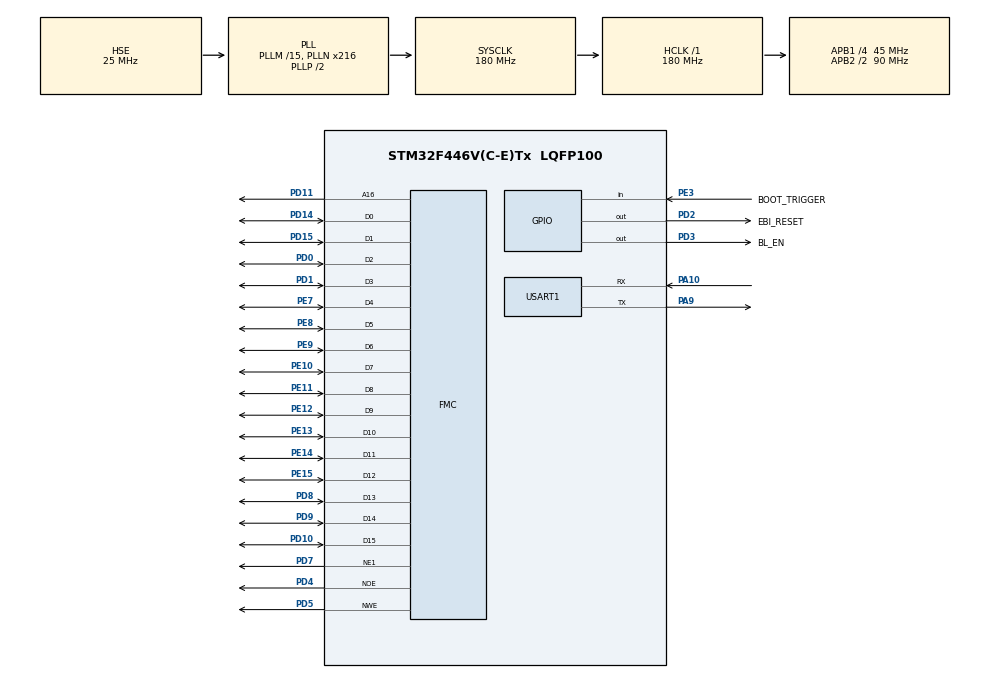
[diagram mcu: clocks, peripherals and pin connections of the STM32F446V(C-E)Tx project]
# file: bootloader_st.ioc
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Mcu.Family=STM32F4
Mcu.Name=STM32F446V(C-E)Tx
Mcu.Package=LQFP100
NVIC.PriorityGroup=NVIC_PRIORITYGROUP_4
NVIC.USART1_IRQn=true\:0\:0\:false\:false\:true
PA10.Mode=Asynchronous
PA10.Signal=USART1_RX
PA9.Mode=Asynchronous
PA9.Signal=USART1_TX
PD0.Mode=16b-d1
PD0.Signal=FMC_D2
PD1.Mode=16b-d1
PD1.Signal=FMC_D3
PD10.Mode=16b-d1
PD10.Signal=FMC_D15
PD11.Mode=A16_1
PD11.Signal=FMC_A16
PD14.Mode=16b-d1
PD14.Signal=FMC_D0
PD15.Mode=16b-d1
PD15.Signal=FMC_D1
PD2.GPIO_Label=EBI_RESET
PD2.Signal=GPIO_Output
PD3.GPIO_Label=BL_EN
PD3.Signal=GPIO_Output
PD4.Mode=Lcd1
PD4.Signal=FMC_NOE
PD5.Mode=Lcd1
PD5.Signal=FMC_NWE
PD7.Mode=NorPsramChipSelect1_1
PD7.Signal=FMC_NE1
PD8.Mode=16b-d1
PD8.Signal=FMC_D13
PD9.Mode=16b-d1
PD9.Signal=FMC_D14
PE10.Mode=16b-d1
PE10.Signal=FMC_D7
PE11.Mode=16b-d1
PE11.Signal=FMC_D8
PE12.Mode=16b-d1
PE12.Signal=FMC_D9
PE13.Mode=16b-d1
PE13.Signal=FMC_D10
PE14.Mode=16b-d1
PE14.Signal=FMC_D11
PE15.Mode=16b-d1
PE15.Signal=FMC_D12
PE3.GPIO_Label=BOOT_TRIGGER
PE3.Signal=GPIO_Input
PE7.Mode=16b-d1
PE7.Signal=FMC_D4
PE8.Mode=16b-d1
PE8.Signal=FMC_D5
PE9.Mode=16b-d1
PE9.Signal=FMC_D6
PH0-OSC_IN.Mode=HSE-External-Oscillator
PH0-OSC_IN.Signal=RCC_OSC_IN
PH1-OSC_OUT.Mode=HSE-External-Oscillator
PH1-OSC_OUT.Signal=RCC_OSC_OUT
ProjectManager.HeapSize=0x200
ProjectManager.StackSize=0x400
ProjectManager.TargetToolchain=EWARM
RCC.AHBFreq_Value=180000000
RCC.APB1CLKDivider=RCC_HCLK_DIV4
RCC.APB1Freq_Value=45000000
RCC.APB1TimFreq_Value=90000000
RCC.APB2CLKDivider=RCC_HCLK_DIV2
RCC.APB2Freq_Value=90000000
RCC.APB2TimFreq_Value=180000000
RCC.CortexFreq_Value=180000000
RCC.HCLKFreq_Value=180000000
RCC.PLLM=15
RCC.PLLN=216
RCC.PLLSourceVirtual=RCC_PLLSOURCE_HSE
RCC.SYSCLKFreq_VALUE=180000000
RCC.SYSCLKSource=RCC_SYSCLKSOURCE_PLLCLK
RCC.USBFreq_Value=180000000
RCC.VCOOutputFreq_Value=360000000
USART1.VirtualMode=VM_ASYNC
board=bootloader_st

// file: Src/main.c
/**
  ******************************************************************************
  * File Name          : main.c
  * Description        : Main program body
  ******************************************************************************
  ** This notice applies to any and all portions of this file
  * that are not between comment pairs USER CODE BEGIN and
  * USER CODE END. Other portions of this file, whether
  * inserted by the user or by software development tools
  * are owned by their respective copyright owners.
  *
  * COPYRIGHT(c) 2017 STMicroelectronics
  *
  * Redistribution and use in source and binary forms, with or without modification,
  * are permitted provided that the following conditions are met:
  *   1. Redistributions of source code must retain the above copyright notice,
  *      this list of conditions and the following disclaimer.
  *   2. Redistributions in binary form must reproduce the above copyright notice,
  *      this list of conditions and the following disclaimer in the documentation
  *      and/or other materials provided with the distribution.
  *   3. Neither the name of STMicroelectronics nor the names of its contributors
  *      may be used to endorse or promote products derived from this software
  *      without specific prior written permission.
  *
  * THIS SOFTWARE IS PROVIDED BY THE COPYRIGHT HOLDERS AND CONTRIBUTORS "AS IS"
  * AND ANY EXPRESS OR IMPLIED WARRANTIES, INCLUDING, BUT NOT LIMITED TO, THE
  * IMPLIED WARRANTIES OF MERCHANTABILITY AND FITNESS FOR A PARTICULAR PURPOSE ARE
  * DISCLAIMED. IN NO EVENT SHALL THE COPYRIGHT HOLDER OR CONTRIBUTORS BE LIABLE
  * FOR ANY DIRECT, INDIRECT, INCIDENTAL, SPECIAL, EXEMPLARY, OR CONSEQUENTIAL
  * DAMAGES (INCLUDING, BUT NOT LIMITED TO, PROCUREMENT OF SUBSTITUTE GOODS OR
  * SERVICES; LOSS OF USE, DATA, OR PROFITS; OR BUSINESS INTERRUPTION) HOWEVER
  * CAUSED AND ON ANY THEORY OF LIABILITY, WHETHER IN CONTRACT, STRICT LIABILITY,
  * OR TORT (INCLUDING NEGLIGENCE OR OTHERWISE) ARISING IN ANY WAY OUT OF THE USE
  * OF THIS SOFTWARE, EVEN IF ADVISED OF THE POSSIBILITY OF SUCH DAMAGE.
  *
  ******************************************************************************
  */
#include "main.h"
#include "stm32f4xx_hal.h"

/* USER CODE BEGIN Includes */
#include "bootloader.h"
/* USER CODE END Includes */

UART_HandleTypeDef huart1;

SRAM_HandleTypeDef hsram1;

/* USER CODE BEGIN PV */
/* Private variables ---------------------------------------------------------*/

/* USER CODE END PV */

void SystemClock_Config(void);
static void MX_GPIO_Init(void);
static void MX_FMC_Init(void);
static void MX_USART1_UART_Init(void);

/* USER CODE BEGIN PFP */
/* Private function prototypes -----------------------------------------------*/
#ifdef __GNUC__
/* With GCC, small printf (option LD Linker->Libraries->Small printf
   set to 'Yes') calls __io_putchar() */
#define PUTCHAR_PROTOTYPE int __io_putchar(int ch)
#else
#define PUTCHAR_PROTOTYPE int fputc(int ch, FILE *f)
#endif /* __GNUC__ */

/* USER CODE END PFP */

int main(void)
{

  /* MCU Configuration----------------------------------------------------------*/

  /* Reset of all peripherals, Initializes the Flash interface and the Systick. */
  HAL_Init();

  /* Configure the system clock */
  SystemClock_Config();

  /* Initialize all configured peripherals */
  MX_GPIO_Init();
  MX_FMC_Init();
  MX_USART1_UART_Init();

  /* USER CODE BEGIN 2 */
  Bootloader_Initialize();

  /* USER CODE END 2 */

  /* Infinite loop */
  /* USER CODE BEGIN WHILE */
  while (1)
  {
        Bootloader_Tasks();

  /* USER CODE END WHILE */

  }

}

/** System Clock Configuration
*/
void SystemClock_Config(void)
{

  RCC_OscInitTypeDef RCC_OscInitStruct;
  RCC_ClkInitTypeDef RCC_ClkInitStruct;

    /**Configure the main internal regulator output voltage
    */
  __HAL_RCC_PWR_CLK_ENABLE();

  __HAL_PWR_VOLTAGESCALING_CONFIG(PWR_REGULATOR_VOLTAGE_SCALE1);

    /**Initializes the CPU, AHB and APB busses clocks
    */
  RCC_OscInitStruct.OscillatorType = RCC_OSCILLATORTYPE_HSE;
  RCC_OscInitStruct.HSEState = RCC_HSE_ON;
  RCC_OscInitStruct.PLL.PLLState = RCC_PLL_ON;
  RCC_OscInitStruct.PLL.PLLSource = RCC_PLLSOURCE_HSE;
  RCC_OscInitStruct.PLL.PLLM = 15;
  RCC_OscInitStruct.PLL.PLLN = 216;
  RCC_OscInitStruct.PLL.PLLP = RCC_PLLP_DIV2;
  RCC_OscInitStruct.PLL.PLLQ = 2;
  RCC_OscInitStruct.PLL.PLLR = 2;
  if (HAL_RCC_OscConfig(&RCC_OscInitStruct) != HAL_OK)
  {
    _Error_Handler(__FILE__, __LINE__);
  }

    /**Activate the Over-Drive mode
    */
  if (HAL_PWREx_EnableOverDrive() != HAL_OK)
  {
    _Error_Handler(__FILE__, __LINE__);
  }

    /**Initializes the CPU, AHB and APB busses clocks
    */
  RCC_ClkInitStruct.ClockType = RCC_CLOCKTYPE_HCLK|RCC_CLOCKTYPE_SYSCLK
                              |RCC_CLOCKTYPE_PCLK1|RCC_CLOCKTYPE_PCLK2;
  RCC_ClkInitStruct.SYSCLKSource = RCC_SYSCLKSOURCE_PLLCLK;
  RCC_ClkInitStruct.AHBCLKDivider = RCC_SYSCLK_DIV1;
  RCC_ClkInitStruct.APB1CLKDivider = RCC_HCLK_DIV4;
  RCC_ClkInitStruct.APB2CLKDivider = RCC_HCLK_DIV2;

  if (HAL_RCC_ClockConfig(&RCC_ClkInitStruct, FLASH_LATENCY_5) != HAL_OK)
  {
    _Error_Handler(__FILE__, __LINE__);
  }

    /**Configure the Systick interrupt time
    */
  HAL_SYSTICK_Config(HAL_RCC_GetHCLKFreq()/1000);

    /**Configure the Systick
    */
  HAL_SYSTICK_CLKSourceConfig(SYSTICK_CLKSOURCE_HCLK);

  /* SysTick_IRQn interrupt configuration */
  HAL_NVIC_SetPriority(SysTick_IRQn, 0, 0);
}

/* USART1 init function */
static void MX_USART1_UART_Init(void)
{

  huart1.Instance = USART1;
  huart1.Init.BaudRate = 115200;
  huart1.Init.WordLength = UART_WORDLENGTH_8B;
  huart1.Init.StopBits = UART_STOPBITS_1;
  huart1.Init.Parity = UART_PARITY_NONE;
  huart1.Init.Mode = UART_MODE_TX_RX;
  huart1.Init.HwFlowCtl = UART_HWCONTROL_NONE;
  huart1.Init.OverSampling = UART_OVERSAMPLING_16;
  if (HAL_UART_Init(&huart1) != HAL_OK)
  {
    _Error_Handler(__FILE__, __LINE__);
  }

}
/* FMC initialization function */
static void MX_FMC_Init(void)
{
  FMC_NORSRAM_TimingTypeDef Timing;

  /** Perform the SRAM1 memory initialization sequence
  */
  hsram1.Instance = FMC_NORSRAM_DEVICE;
  hsram1.Extended = FMC_NORSRAM_EXTENDED_DEVICE;
  /* hsram1.Init */
  hsram1.Init.NSBank = FMC_NORSRAM_BANK1;
  hsram1.Init.DataAddressMux = FMC_DATA_ADDRESS_MUX_DISABLE;
  hsram1.Init.MemoryType = FMC_MEMORY_TYPE_SRAM;
  hsram1.Init.MemoryDataWidth = FMC_NORSRAM_MEM_BUS_WIDTH_16;
  hsram1.Init.BurstAccessMode = FMC_BURST_ACCESS_MODE_DISABLE;
  hsram1.Init.WaitSignalPolarity = FMC_WAIT_SIGNAL_POLARITY_LOW;
  hsram1.Init.WaitSignalActive = FMC_WAIT_TIMING_BEFORE_WS;
  hsram1.Init.WriteOperation = FMC_WRITE_OPERATION_ENABLE;
  hsram1.Init.WaitSignal = FMC_WAIT_SIGNAL_DISABLE;
  hsram1.Init.ExtendedMode = FMC_EXTENDED_MODE_DISABLE;
  hsram1.Init.AsynchronousWait = FMC_ASYNCHRONOUS_WAIT_DISABLE;
  hsram1.Init.WriteBurst = FMC_WRITE_BURST_DISABLE;
  hsram1.Init.ContinuousClock = FMC_CONTINUOUS_CLOCK_SYNC_ONLY;
  hsram1.Init.WriteFifo = FMC_WRITE_FIFO_ENABLE;
  hsram1.Init.PageSize = FMC_PAGE_SIZE_NONE;
  /* Timing */
  Timing.AddressSetupTime = 15;
  Timing.AddressHoldTime = 15;
  Timing.DataSetupTime = 30;
  Timing.BusTurnAroundDuration = 15;
  Timing.CLKDivision = 16;
  Timing.DataLatency = 17;
  Timing.AccessMode = FMC_ACCESS_MODE_A;
  /* ExtTiming */

  if (HAL_SRAM_Init(&hsram1, &Timing, NULL) != HAL_OK)
  {
    _Error_Handler(__FILE__, __LINE__);
  }

}

/** Configure pins as
        * Analog
        * Input
        * Output
        * EVENT_OUT
        * EXTI
*/
static void MX_GPIO_Init(void)
{

  GPIO_InitTypeDef GPIO_InitStruct;

  /* GPIO Ports Clock Enable */
  __HAL_RCC_GPIOE_CLK_ENABLE();
  __HAL_RCC_GPIOH_CLK_ENABLE();
  __HAL_RCC_GPIOD_CLK_ENABLE();
  __HAL_RCC_GPIOA_CLK_ENABLE();

  /*Configure GPIO pin Output Level */
  HAL_GPIO_WritePin(GPIOD, EBI_RESET_Pin|BL_EN_Pin, GPIO_PIN_RESET);

  /*Configure GPIO pin : BOOT_TRIGGER_Pin */
  GPIO_InitStruct.Pin = BOOT_TRIGGER_Pin;
  GPIO_InitStruct.Mode = GPIO_MODE_INPUT;
  GPIO_InitStruct.Pull = GPIO_NOPULL;
  HAL_GPIO_Init(BOOT_TRIGGER_GPIO_Port, &GPIO_InitStruct);

  /*Configure GPIO pins : EBI_RESET_Pin BL_EN_Pin */
  GPIO_InitStruct.Pin = EBI_RESET_Pin|BL_EN_Pin;
  GPIO_InitStruct.Mode = GPIO_MODE_OUTPUT_PP;
  GPIO_InitStruct.Pull = GPIO_NOPULL;
  GPIO_InitStruct.Speed = GPIO_SPEED_FREQ_LOW;
  HAL_GPIO_Init(GPIOD, &GPIO_InitStruct);

}

/* USER CODE BEGIN 4 */
/**
  * @brief  Retargets the C library printf function to the USART.
  * @param  None
  * @retval None
  */
PUTCHAR_PROTOTYPE
{
  /* Place your implementation of fputc here */
  /* e.g. write a character to the USART1 and Loop until the end of transmission */
  HAL_UART_Transmit(&huart1, (uint8_t *)&ch, 1, 0xFFFF);

  return ch;
}
/* USER CODE END 4 */

void _Error_Handler(char * file, int line)
{
  while(1)
  {
  }
}

/************************ (C) COPYRIGHT STMicroelectronics *****END OF FILE****/
